# ADC_1 register map
Vendor: Texas Instruments
Peripheral module from a debugger description file (folder msp430).
Registers are 16-bit, access not given, no defined reset value unless marked. A register's access mark holds for its fields unless they carry their own. Offsets are as the file gives them; lines under a group give offsets from that group; [hi:lo] are bit positions; {n}, {i} and the like mark numbered series; 'fields as' and 'values as' point back to an identical list; <NAME> marks a mode.

## ADC
0x110 AIN — ADC Input
0x112 AEN — ADC Input Enable
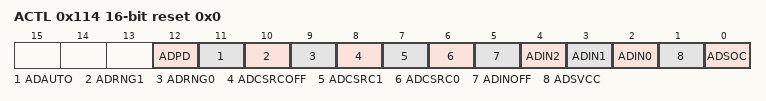
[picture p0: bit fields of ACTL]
0x114 ACTL rw reset 0x0 — ADC Control
  [12] ADPD, [11] ADAUTO, [10] ADRNG1, [9] ADRNG0, [8] ADCSRCOFF, [7] ADCSRC1, [6] ADCSRC0, [5] ADINOFF, [4] ADIN2, [3] ADIN1, [2] ADIN0, [1] ADSVCC, [0] ADSOC
0x118 ADAT — ADC Data
